# Operational_Amplifier_1 register map
Vendor: Texas Instruments
Peripheral module from a debugger description file (folder msp430).
Registers are 8-bit, read-write, reset 0x0 unless marked. A register's access mark holds for its fields unless they carry their own. Offsets are as the file gives them; lines under a group give offsets from that group; [hi:lo] are bit positions; {n}, {i} and the like mark numbered series; 'fields as' and 'values as' point back to an identical list; <NAME> marks a mode.

## Operational_Amplifier
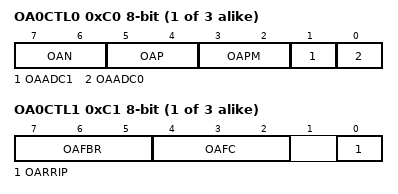
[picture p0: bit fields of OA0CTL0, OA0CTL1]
{0xC0+2i} OA{i}CTL0 (i=0..2) — OA{i} Control register 0
  [7:6] OAN — OAx Inverting input select 0
    0=OAx Inverting input select 00; 1=OAx Inverting input select 01; 2=OAx Inverting input select 10; 3=OAx Inverting input select 11
  [5:4] OAP — OAx Non-inverting input select 0
    0=OAx Non-inverting input select 00; 1=OAx Non-inverting input select 01; 2=OAx Non-inverting input select 10; 3=OAx Non-inverting input select 11
  [3:2] OAPM — OAx Power mode select 0
    0=OAx Power mode select: off; 1=OAx Power mode select: slow; 2=OAx Power mode select: meduim; 3=OAx Power mode select: fast
  [1] OAADC1 — OAx output to ADC12 input channel select 1
  [0] OAADC0 — OAx output to ADC12 input channel select 0
{0xC1+2i} OA{i}CTL1 (i=0..2) — OA{i} Control register 1
  [7:5] OAFBR — OAx Feedback resistor select 0
    {v}=OAx Feedback resistor: Tap {v} (v=0..7)
  [4:2] OAFC — OAx Function control 0
    0=OAx Function: Gen. Purpose; 1=OAx Function: Unity gain buffer; 2=OAx Function: Reserved; 3=OAx Function: Comparator; 4=OAx Function: Non-Inverting PGA; 5=OAx Function: Reserved; 6=OAx Function: Inverting PGA; 7=OAx Function: Differential PGA
  [0] OARRIP — OAx Rail-to-Rail Input off
